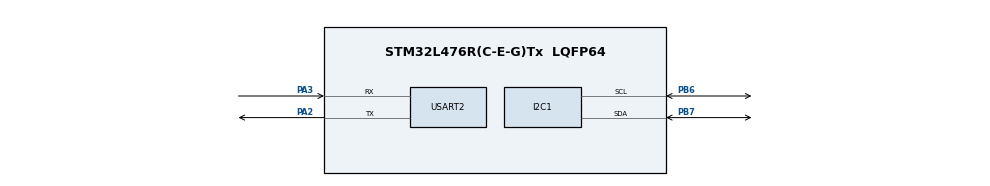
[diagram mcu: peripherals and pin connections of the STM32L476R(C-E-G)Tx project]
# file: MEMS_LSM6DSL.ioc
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Mcu.Family=STM32L4
Mcu.Name=STM32L476R(C-E-G)Tx
Mcu.Package=LQFP64
NVIC.PriorityGroup=NVIC_PRIORITYGROUP_4
PA2.Mode=Asynchronous
PA2.Signal=USART2_TX
PA3.Mode=Asynchronous
PA3.Signal=USART2_RX
PB6.Mode=I2C
PB6.Signal=I2C1_SCL
PB7.Mode=I2C
PB7.Signal=I2C1_SDA
ProjectManager.HeapSize=0x200
ProjectManager.StackSize=0x400
ProjectManager.TargetToolchain=STM32CubeIDE
RCC.HSE_VALUE=8000000
RCC.HSI_VALUE=16000000
RCC.LSE_VALUE=32768
RCC.MSI_VALUE=4000000
RCC.VCOOutputFreq_Value=32000000
USART2.VirtualMode-Asynchronous=VM_ASYNC
board=custom

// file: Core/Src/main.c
/* USER CODE BEGIN Header */
/**
  ******************************************************************************
  * @file           : main.c
  * @brief          : Main program body
  ******************************************************************************
  * @attention
  *
  * Copyright (c) 2023 STMicroelectronics.
  * All rights reserved.
  *
  * This software is licensed under terms that can be found in the LICENSE file
  * in the root directory of this software component.
  * If no LICENSE file comes with this software, it is provided AS-IS.
  *
  ******************************************************************************
  */
/* USER CODE END Header */
#include "main.h"
#include "i2c.h"
#include "usart.h"
#include "gpio.h"

/* USER CODE BEGIN Includes */
#include "lsm6dsl.h"
#include "ioputchar.h"
/* USER CODE END Includes */

/* USER CODE BEGIN PV */
LSM6DSL_Axes_t accel_axes;
LSM6DSL_Axes_t gyro_axes;
/* USER CODE END PV */

void SystemClock_Config(void);

int main(void)
{

  /* MCU Configuration--------------------------------------------------------*/

  /* Reset of all peripherals, Initializes the Flash interface and the Systick. */
  HAL_Init();

  /* Configure the system clock */
  SystemClock_Config();

  /* Initialize all configured peripherals */
  MX_GPIO_Init();
  MX_I2C1_Init();
  MX_USART2_UART_Init();
  /* USER CODE BEGIN 2 */
  lsm6dsl_init();
  /* USER CODE END 2 */

  /* Infinite loop */
  while (1)
  {

    /* USER CODE BEGIN 3 */
	  lsm6dsl_get_accel_axis(&accel_axes);
	  lsm6dsl_get_gyro_axis(&gyro_axes);
	  printf("\033[27\033[H\nGyro: \nX = %ld    \nY = %ld    \nZ = %ld    \n", gyro_axes.x, gyro_axes.y, gyro_axes.z);
	  printf("Acc: \nX = %ld   \nY = %ld   \nZ = %ld        \n", accel_axes.x, accel_axes.y, accel_axes.z);
	  LL_mDelay(100);
  }
  /* USER CODE END 3 */
}

void SystemClock_Config(void)
{
  LL_FLASH_SetLatency(LL_FLASH_LATENCY_0);
  while(LL_FLASH_GetLatency()!= LL_FLASH_LATENCY_0)
  {
  }
  LL_PWR_SetRegulVoltageScaling(LL_PWR_REGU_VOLTAGE_SCALE1);
  LL_RCC_MSI_Enable();

   /* Wait till MSI is ready */
  while(LL_RCC_MSI_IsReady() != 1)
  {

  }
  LL_RCC_MSI_EnableRangeSelection();
  LL_RCC_MSI_SetRange(LL_RCC_MSIRANGE_6);
  LL_RCC_MSI_SetCalibTrimming(0);
  LL_RCC_SetSysClkSource(LL_RCC_SYS_CLKSOURCE_MSI);

   /* Wait till System clock is ready */
  while(LL_RCC_GetSysClkSource() != LL_RCC_SYS_CLKSOURCE_STATUS_MSI)
  {

  }
  LL_RCC_SetAHBPrescaler(LL_RCC_SYSCLK_DIV_1);
  LL_RCC_SetAPB1Prescaler(LL_RCC_APB1_DIV_1);
  LL_RCC_SetAPB2Prescaler(LL_RCC_APB2_DIV_1);
  LL_SetSystemCoreClock(4000000);

   /* Update the time base */
  if (HAL_InitTick (TICK_INT_PRIORITY) != HAL_OK)
  {
    Error_Handler();
  }
}

void Error_Handler(void)
{
  __disable_irq();
  while (1)
  {
  }
}
